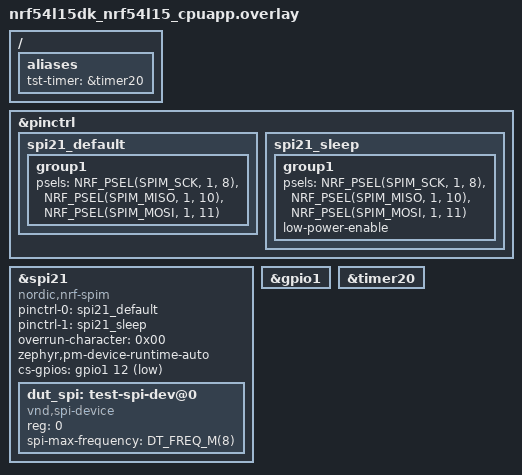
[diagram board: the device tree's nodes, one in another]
/*
 * Copyright (c) 2025 Nordic Semiconductor ASA
 *
 * SPDX-License-Identifier: LicenseRef-Nordic-5-Clause
 */

/* Required loopbacks:
 * P2.08 <-> P2.09
 */

/ {
	aliases {
		tst-timer = &timer20;
	};
};

&pinctrl {
	spi21_default: spi21_default {
		group1 {
			psels = <NRF_PSEL(SPIM_SCK, 1, 8)>,
				<NRF_PSEL(SPIM_MISO, 1, 10)>,
				<NRF_PSEL(SPIM_MOSI, 1, 11)>;
		};
	};

	spi21_sleep: spi21_sleep {
		group1 {
			psels = <NRF_PSEL(SPIM_SCK, 1, 8)>,
				<NRF_PSEL(SPIM_MISO, 1, 10)>,
				<NRF_PSEL(SPIM_MOSI, 1, 11)>;
			low-power-enable;
		};
	};
};

&spi21 {
	compatible = "nordic,nrf-spim";
	status = "okay";
	pinctrl-0 = <&spi21_default>;
	pinctrl-1 = <&spi21_sleep>;
	pinctrl-names = "default", "sleep";
	overrun-character = <0x00>;
	zephyr,pm-device-runtime-auto;
	cs-gpios = <&gpio1 12 GPIO_ACTIVE_LOW>;
	dut_spi: test-spi-dev@0 {
		compatible = "vnd,spi-device";
		reg = <0>;
		spi-max-frequency = <DT_FREQ_M(8)>;
	};
};

&gpio1 {
	status = "okay";
};

&timer20 {
	status = "okay";
};
